VERSION ""

NS_ :

BS_:

BU_: XXX

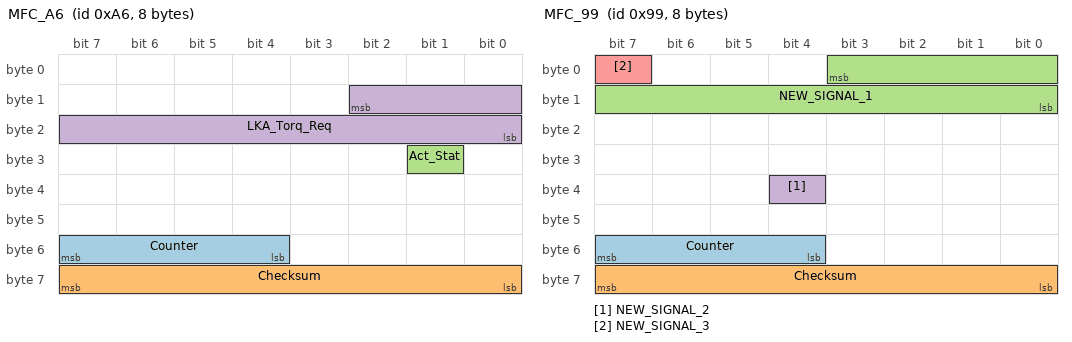
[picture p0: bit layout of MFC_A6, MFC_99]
BO_ 166 MFC_A6: 8 XXX
 SG_ Counter : 55|4@0+ (1,0) [0|15] "" XXX
 SG_ Checksum : 63|8@0+ (1,0) [0|255] "" XXX
 SG_ Act_Stat : 25|1@0+ (1,0) [0|1] "" XXX
 SG_ LKA_Torq_Req : 10|11@0+ (1,-1024) [0|7] "" XXX

BO_ 121 VS_79: 8 XXX
 SG_ Counter : 55|4@0+ (1,0) [0|15] "" XXX
 SG_ Checksum : 63|8@0+ (1,0) [0|255] "" XXX
 SG_ VS : 39|16@0+ (1,0) [0|255] "" XXX
 SG_ UNKNOWN1 : 2|11@0+ (1,0) [0|255] "" XXX
 SG_ UNKNOWN2 : 18|13@0+ (1,0) [0|65535] "" XXX
 SG_ Stationary_FLAG : 7|1@0+ (1,0) [0|1] "" XXX

BO_ 153 MFC_99: 8 XXX
 SG_ Counter : 55|4@0+ (1,0) [0|3] "" XXX
 SG_ Checksum : 63|8@0+ (1,0) [0|3] "" XXX
 SG_ NEW_SIGNAL_1 : 3|12@0+ (1,0) [0|511] "" XXX
 SG_ NEW_SIGNAL_2 : 36|1@0+ (1,0) [0|1] "" XXX
 SG_ NEW_SIGNAL_3 : 7|1@0+ (1,0) [0|1] "" XXX

BO_ 163 MFC_A3: 8 XXX
 SG_ UNKNOWN1 : 63|8@0+ (1,0) [0|255] "" XXX

BO_ 232 MFC_E8: 8 XXX
 SG_ Target_Distance : 63|8@0+ (1,0) [0|255] "" XXX

BO_ 250 MFC_FA: 8 XXX
 SG_ STAT_1 : 10|3@0+ (1,0) [0|7] "" XXX
 SG_ STAT_2 : 48|3@1+ (1,0) [0|3] "" XXX

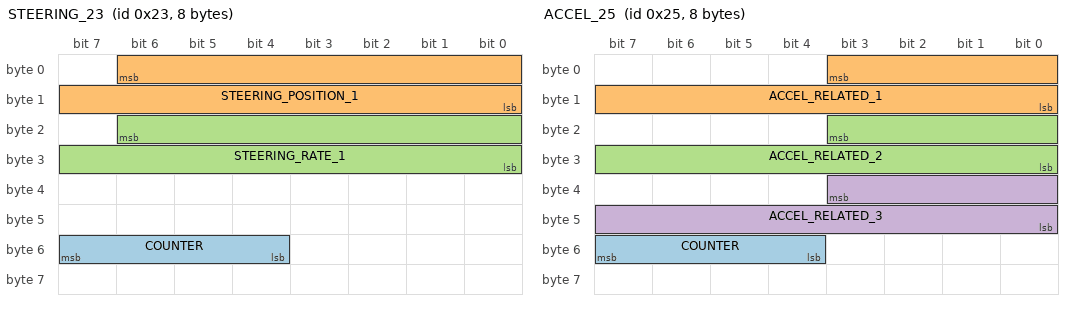
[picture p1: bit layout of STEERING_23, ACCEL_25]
BO_ 35 STEERING_23: 8 XXX
 SG_ COUNTER : 55|4@0+ (1,0) [0|15] "" XXX
 SG_ STEERING_POSITION_1 : 6|15@0+ (1,0) [0|255] "" XXX
 SG_ STEERING_RATE_1 : 22|15@0+ (1,0) [0|32767] "" XXX

BO_ 37 ACCEL_25: 8 XXX
 SG_ COUNTER : 55|4@0+ (1,0) [0|15] "" XXX
 SG_ ACCEL_RELATED_1 : 3|12@0+ (1,0) [0|65535] "" XXX
 SG_ ACCEL_RELATED_2 : 19|12@0+ (1,0) [0|4095] "" XXX
 SG_ ACCEL_RELATED_3 : 35|12@0+ (1,0) [0|4095] "" XXX

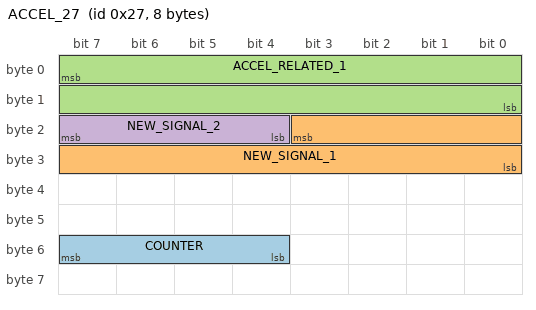
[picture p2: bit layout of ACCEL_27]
BO_ 39 ACCEL_27: 8 XXX
 SG_ COUNTER : 55|4@0+ (1,0) [0|15] "" XXX
 SG_ NEW_SIGNAL_1 : 19|12@0+ (1,0) [0|4095] "" XXX
 SG_ ACCEL_RELATED_1 : 7|16@0+ (1,0) [0|4095] "" XXX
 SG_ NEW_SIGNAL_2 : 23|4@0+ (1,0) [0|15] "" XXX
